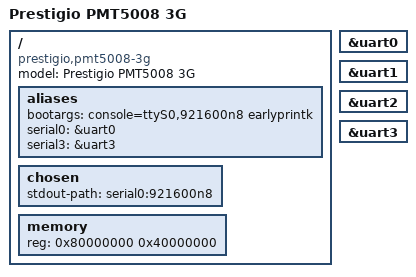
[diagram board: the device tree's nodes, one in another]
// SPDX-License-Identifier: GPL-2.0+
/*
 * Copyright (c) 2021 Maxim Kutnij <gtk3@inbox.ru>
 */

/dts-v1/;
#include "mt6582.dtsi"

/ {
	model = "Prestigio PMT5008 3G";
	compatible = "prestigio,pmt5008-3g", "mediatek,mt6582";

	aliases {
		bootargs = "console=ttyS0,921600n8 earlyprintk";
		serial0 = &uart0;
		serial3 = &uart3;
	};

	chosen {
		stdout-path = "serial0:921600n8";
	};

	memory {
		device_type = "memory";
		reg = <0x80000000 0x40000000>;
	};
};

&uart0 {
	status = "okay";
};

&uart1 {
	status = "okay";
};

&uart2 {
	status = "okay";
};

&uart3 {
	status = "okay";
};
